# LPC11Axx register map
File version: 0.6
CPU: CM0 r0p0, little endian, no MPU, no FPU, 2 interrupt priority bits
Registers are 32-bit, read-write, reset 0x0 unless marked. A register's access mark holds for its fields unless they carry their own. Offsets are from the block's base; [hi:lo] are bit positions; {n}, {i} and the like mark numbered series; 'fields as' and 'values as' point back to an identical list.

## SYSCON — System configuration
Base 0x40048000
0x00 SYSMEMREMAP reset 0x2 — System memory remap
  [1:0] MAP
    0=BOOT_LOADER_MODE_IN (Boot Loader Mode. Interrupt vectors are re-mapped to Boot ROM.); 1=USER_RAM_MODE_INTER (User RAM Mode. Interrupt vectors are re-mapped to Static RAM.); 2=USER_FLASH_MODE_INT (User Flash Mode. Interrupt vectors are not re-mapped and reside in Flash.)
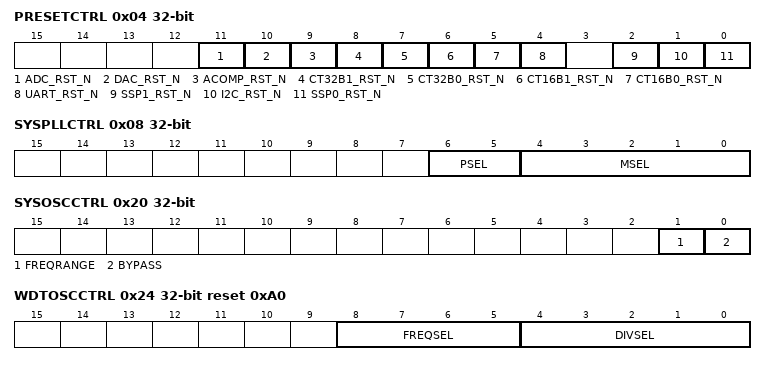
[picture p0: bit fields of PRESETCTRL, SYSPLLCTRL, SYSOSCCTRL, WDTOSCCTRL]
0x04 PRESETCTRL — Peripheral reset control
  [11] ADC_RST_N — ADC reset control
    0=RESETS_THE_ADC_PERIP (Resets the ADC peripheral.); 1=ADC_RESET_DE_ASSERTE (ADC reset de-asserted.)
  [10] DAC_RST_N — DAC reset control
    0=RESETS_THE_DAC_PERIP (Resets the DAC peripheral.); 1=DAC_RESET_DE_ASSERTE (DAC reset de-asserted.)
  [9] ACOMP_RST_N — Analog comparator reset control
    0=RESETS_THE_ANALOG_CO (Resets the Analog comparator peripheral.); 1=ANALOG_COMPARATOR_RE (Analog comparator reset de-asserted.)
  [8] CT32B1_RST_N — CT32B1 reset control
    0=RESETS_THE_CT32B1_PE (Resets the CT32B1 peripheral.); 1=CT32B1_RESET_DE_ASSE (CT32B1 reset de-asserted.)
  [7] CT32B0_RST_N — CT32B0 reset control
    0=RESETS_THE_CT32B0_PE (Resets the CT32B0 peripheral.); 1=CT32B0_RESET_DE_ASSE (CT32B0 reset de-asserted.)
  [6] CT16B1_RST_N — CT16B1 reset control
    0=RESETS_THE_CT16B1_PE (Resets the CT16B1 peripheral.); 1=CT16B1_RESET_DE_ASSE (CT16B1 reset de-asserted.)
  [5] CT16B0_RST_N — CT16B0 reset control
    0=RESETS_THE_CT16B0_PE (Resets the CT16B0 peripheral.); 1=CT16B0_RESET_DE_ASSE (CT16B0 reset de-asserted.)
  [4] UART_RST_N — UART reset control
    0=RESETS_THE_UART_PERI (Resets the UART peripheral.); 1=UART_RESET_DE_ASSERT (UART reset de-asserted.)
  [2] SSP1_RST_N — SSP1 reset control
    0=RESETS_THE_SSP1_PERI (Resets the SSP1 peripheral.); 1=SSP1_RESET_DE_ASSERT (SSP1 reset de-asserted.)
  [1] I2C_RST_N — I2C reset control
    0=RESETS_THE_I2C_PERIP (Resets the I2C peripheral.); 1=I2C_RESET_DE_ASSERTE (I2C reset de-asserted.)
  [0] SSP0_RST_N — SSP0 reset control
    0=RESETS_THE_SSP0_PERI (Resets the SSP0 peripheral.); 1=SSP0_RESET_DE_ASSERT (SSP0 reset de-asserted.)
0x08 SYSPLLCTRL — System PLL control
  [6:5] PSEL — Post divider ratio P. The division ratio is 2 x P.
    0=P_EQ_1 (P = 1); 1=P_EQ_2 (P = 2); 2=P_EQ_4 (P = 4); 3=P_EQ_8 (P = 8)
  [4:0] MSEL — Feedback divider value. The division value M is the programmed MSEL value + 1. 00000: Division ratio M = 1 to 11111: Division ratio M = 32
0x0C SYSPLLSTAT ro — System PLL status
  [0] LOCK — PLL lock status
    0=PLL_NOT_LOCKED; 1=PLL_LOCKED
0x20 SYSOSCCTRL — System oscillator control
  [1] FREQRANGE — Determines frequency range for Low-power oscillator.
    0=1__20_MHZ_FREQUENCY (1 - 20 MHz frequency range.); 1=15__25_MHZ_FREQUENC (15 - 25 MHz frequency range)
  [0] BYPASS — Bypass system oscillator
    0=OSCILLATOR_IS_NOT_BY (Oscillator is not bypassed.); 1=BYPASS_ENABLED_PLL_ (Bypass enabled. PLL input (sys_osc_clk) is fed directly from the XTALIN pins.)
0x24 WDTOSCCTRL reset 0xA0 — Watchdog oscillator control
  [8:5] FREQSEL — Select watchdog oscillator analog output frequency (Fclkana).
    0=OPERATION_IS_UNDEFIN (Operation is undefined for this value. Startup code should program a non-zero value in this field as soon after reset as possible.); 1=0_6_MHZ; 2=1_05_MHZ; 3=1_4_MHZ; 4=1_75_MHZ; 5=2_1_MHZ; 6=2_4_MHZ; 7=2_7_MHZ; 8=3_0_MHZ; 9=3_25_MHZ; 10=3_5_MHZ; 11=3_75_MHZ; 12=4_0_MHZ; 13=4_2_MHZ; 14=4_4_MHZ; 15=4_6_MHZ
  [4:0] DIVSEL — Select divider for Fclkana. wdt_osc_clk = Fclkana/ (2 x (1 + DIVSEL)) 00000: 2 x (1 + DIVSEL) = 2 00001: 2 x (1 + DIVSEL) = 4 to 11111: 2 x (1 + DIVSEL) = 64
0x28 IRCCTRL — IRC oscillator control
  [7:0] TRIM — Trim value
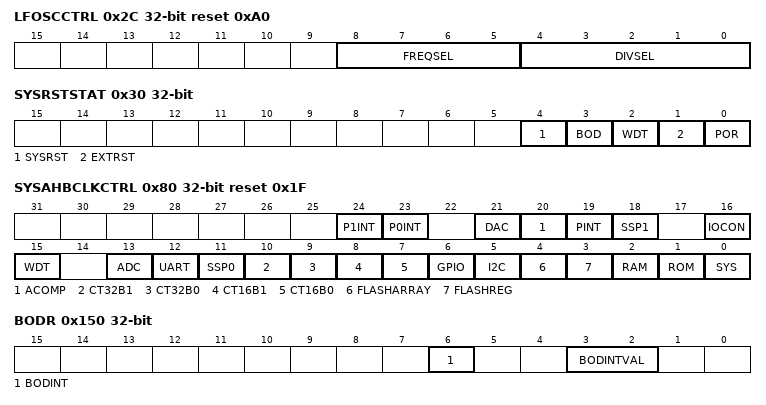
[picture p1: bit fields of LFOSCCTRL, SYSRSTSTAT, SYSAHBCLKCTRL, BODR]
0x2C LFOSCCTRL reset 0xA0 — LF oscillator control
  fields as WDTOSCCTRL
0x30 SYSRSTSTAT — System reset status register
  [4] SYSRST — Status of the software system reset
    0=NO_SYSTEM_RESET_DETE (No System reset detected); 1=SYSTEM_RESET_DETECTE (System reset detected)
  [3] BOD — Status of the Brown-out detect reset
    0=NO_BOD_RESET_DETECTE (No BOD reset detected); 1=BOD_RESET_DETECTED
  [2] WDT — Status of the Watchdog reset
    0=NO_WDT_RESET_DETECTE (No WDT reset detected); 1=WDT_RESET_DETECTED
  [1] EXTRST — External reset status
    0=NO_RESET_EVENT_DETEC (No RESET event detected); 1=RESET_DETECTED
  [0] POR — POR reset status
    0=NO_POR_DETECTED; 1=POR_DETECTED
0x40 SYSPLLCLKSEL — System PLL clock source select
  [1:0] SEL — System PLL clock source
    0=IRC; 1=CRYSTAL_OSCILLATOR_ (Crystal Oscillator (XTAL)); 2=CLKIN_PIN
0x44 SYSPLLCLKUEN — System PLL clock source update enable
  [0] ENA — Enable system PLL clock source update
    0=NO_CHANGE; 1=UPDATE_CLOCK_SOURCE
0x70 MAINCLKSEL — Main clock source select
  [1:0] SEL — Clock source for main clock
    0=IRC_OSCILLATOR; 1=PLL_INPUT; 2=LF_OSCILLATOR; 3=PLL_OUTPUT
0x74 MAINCLKUEN — Main clock source update enable
  [0] ENA — Enable main clock source update
    0=NO_CHANGE; 1=UPDATE_CLOCK_SOURCE
0x78 SYSAHBCLKDIV reset 0x1 — System clock divider
  [7:0] DIV — System AHB clock divider values 0: System clock disabled. 1: Divide by 1. to 255: Divide by 255.
0x80 SYSAHBCLKCTRL reset 0x1F — System clock control
  [24] P1INT — GPIO Port 1interrupt
    0=DISABLE; 1=ENABLE
  [23] P0INT — GPIO Port 0 interrupt
    0=DISABLE; 1=ENABLE
  [21] DAC — Enables clock for DAC.
    0=DISABLE; 1=ENABLE
  [20] ACOMP — Enables clock for ACOMP.
    0=DISABLE; 1=ENABLE
  [19] PINT — GPIO Pin interrupts
    0=DISABLE; 1=ENABLE
  [18] SSP1 — Enables clock for SSP1.
    0=DISABLE; 1=ENABLE
  [16] IOCON — Enables clock for I/O configuration block.
    0=DISABLE; 1=ENABLE
  [15] WDT — Enables clock for WDT.
    0=DISABLE; 1=ENABLE
  [13] ADC — Enables clock for ADC.
    0=DISABLE; 1=ENABLE
  [12] UART — Enables clock for UART. Note that the UART pins must be configured in the IOCON block before the UART clock can be enabled.
    0=DISABLE; 1=ENABLE
  [11] SSP0 — Enables clock for SSP0.
    0=DISABLE; 1=ENABLE
  [10] CT32B1 — Enables clock for 32-bit counter/timer 1.
    0=DISABLE; 1=ENABLE
  [9] CT32B0 — Enables clock for 32-bit counter/timer 0.
    0=DISABLE; 1=ENABLE
  [8] CT16B1 — Enables clock for 16-bit counter/timer 1.
    0=DISABLE; 1=ENABLE
  [7] CT16B0 — Enables clock for 16-bit counter/timer 0.
    0=DISABLE; 1=ENABLE
  [6] GPIO — Enables clock for GPIO.
    0=DISABLE; 1=ENABLE
  [5] I2C — Enables clock for I2C.
    0=DISABLE; 1=ENABLE
  [4] FLASHARRAY — Enables clock for flash/EEPROM array access.
    0=DISABLED; 1=ENABLED
  [3] FLASHREG — Enables clock for flash/EEPROM register interface.
    0=DISABLED; 1=ENABLED
  [2] RAM — Enables clock for RAM.
    0=DISABLE; 1=ENABLE
  [1] ROM — Enables clock for ROM.
    0=DISABLE; 1=ENABLE
  [0] SYS — Enables the clock for the AHB, the APB bridge, the Cortex-M0 FCLK and HCLK, SysCon, and the PMU. This bit is read only and always reads as 1.
    1=ENABLE
0x94 SSP0CLKDIV — SSP0 clock divider
  [7:0] DIV — SSP0_PCLK clock divider values 0: Disable SSP1_PCLK. 1: Divide by 1. to 255: Divide by 255.
0x98 UARTCLKDIV — UART clock divider
  [7:0] DIV — UART_PCLK clock divider values 0: Disable UART_PCLK. 1: Divide by 1. to 255: Divide by 255.
0x9C SSP1CLKDIV — SSP1 clock divider
  [7:0] DIV — SSP1_PCLK clock divider values 0: Disable SSP1_PCLK. 1: Divide by 1. to 255: Divide by 255.
0xE0 CLKOUTSEL — CLKOUT clock source select
  [1:0] SEL — CLKOUT clock source
    0=IRC_OSCILLATOR; 1=CRYSTAL_OSCILLATOR_ (Crystal oscillator (XTAL)); 2=LF_OSCILLATOR; 3=MAIN_CLOCK
0xE4 CLKOUTUEN — CLKOUT clock source update enable
  [0] ENA — Enable CLKOUT clock source update
    0=NO_CHANGE; 1=UPDATE_CLOCK_SOURCE
0xE8 CLKOUTDIV — CLKOUT clock divider
  [7:0] DIV — CLKOUT clock divider values 0: Disable CLKOUT clock divider. 1: Divide by 1. to 255: Divide by 255.
0x100 PIOPORCAP0 ro reset not defined — POR captured PIO status 0
  [31:0] PIOSTAT — State of PIO0_31 through PIO0_0 at power-on reset
0x104 PIOPORCAP1 ro reset not defined — POR captured PIO status 1
  [9:0] PIOSTAT — State of PIO1_9 through PIO1_0 at power-on reset
0x150 BODR — Brown-Out Detect
  [6] BODINT — This bit is 1 if the BOD is requesting an interrupt.
  [3:2] BODINTVAL — BOD interrupt threshold
    2=LEVEL_2_THE_INTERRU (Level 2: the interrupt assertion threshold voltage is 2.52 V; the interrupt de-assertion threshold voltage is 2.66 V.); 3=LEVEL_3_THE_INTERRU (Level 3: the interrupt assertion threshold voltage is 2.80 V; the interrupt de-assertion threshold voltage is 2.90 V.)
0x158 SYSTCKCAL reset 0x4 — System tick counter calibration
  [25:0] CAL — System tick timer calibration value
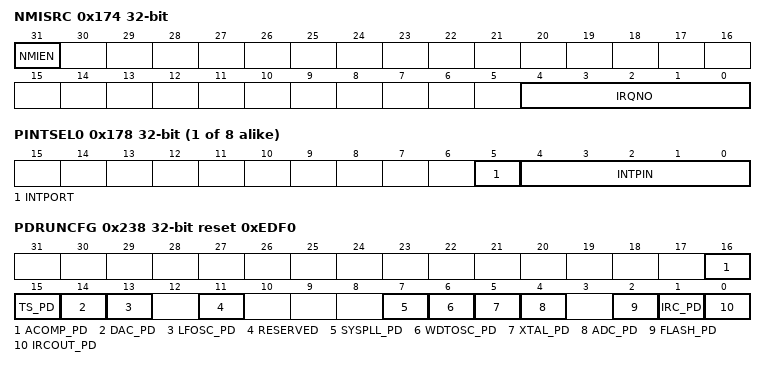
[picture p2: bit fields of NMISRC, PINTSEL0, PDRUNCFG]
0x174 NMISRC — NMI Source Control
  [31] NMIEN — Write a 1 to this bit to enable the Non-Maskable Interrupt (NMI) source selected by bits 4:0.
  [4:0] IRQNO — The IRQ number of the interrupt that is to act as the Non-Maskable interrupt (NMI) if bit 31 is 1. See Section 4.3 for the list of interrupt sources and their IRQ numbers.
{0x178+4i} PINTSEL{i} (i=0..7) — GPIO Pin Interrupt Select register 0
  [5] INTPORT — Select the port: 0 = P0 pin. 1 = P1 pin.
  [4:0] INTPIN — The pin number within the port identified by the INTPORT field.
0x238 PDRUNCFG reset 0xEDF0 — Power configuration register
  [16] ACOMP_PD — Analog Comparator power-down
    1=POWERED_DOWN; 0=POWERED
  [15] TS_PD — Temperature Sensor power-down
    1=POWERED_DOWN; 0=POWERED
  [14] DAC_PD — DAC power-down
    1=POWERED_DOWN; 0=POWERED
  [13] LFOSC_PD — Low frequency oscillator power-down
    1=POWERED_DOWN; 0=POWERED
  [11] RESERVED — Reserved. This bit must be set to one in Run mode.
  [7] SYSPLL_PD — System PLL power-down
    1=POWERED_DOWN; 0=POWERED
  [6] WDTOSC_PD — Watchdog oscillator power-down
    1=POWERED_DOWN; 0=POWERED
  [5] XTAL_PD — Crystal oscillator power-down
    1=POWERED_DOWN; 0=POWERED
  [4] ADC_PD — ADC power-down
    1=POWERED_DOWN; 0=POWERED
  [2] FLASH_PD — Flash power-down
    1=POWERED_DOWN; 0=POWERED
  [1] IRC_PD — IRC oscillator power-down
    1=POWERED_DOWN; 0=POWERED
  [0] IRCOUT_PD — IRC oscillator output power-down
    1=POWERED_DOWN; 0=POWERED
0x3F4 DEVICE_ID ro reset not defined
  [31:0] DEVICEID — Part ID number for LPC11Axx LPC11A11FBD48/001 = 0x455E C02B LPC11A11FHN33/001 = 0x455E C02B LPC11A12FBD48/101 = 0x4574 802B LPC11A12FHN33/101 = 0x4574 802B LPC11A13FBD48/201 = 0x4582 402B LPC11A13FHI33/201 = 0x4582 402B LPC11A14FBD48/301 = 0x35A0 002B; 0x45A0 002B LPC11A14FHN33/301 = 0x35A0 002B; 0x45A0 002B LPC11A02UK = 0x4D5C C02B LPC11A04UK = 0x4D80 002B
